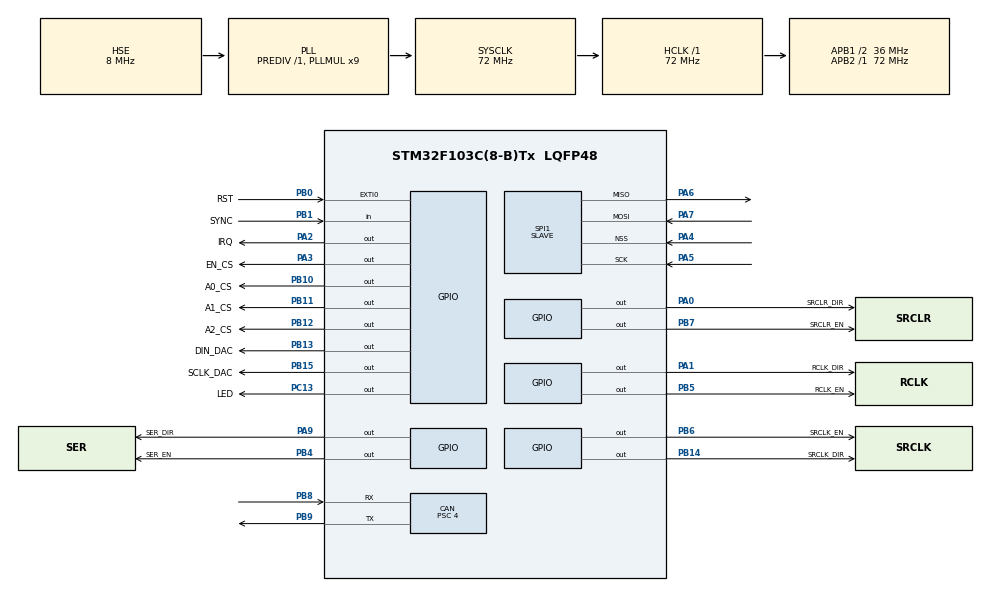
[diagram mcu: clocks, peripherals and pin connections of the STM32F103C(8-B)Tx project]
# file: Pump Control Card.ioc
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CAN.ABOM=ENABLE
CAN.BS1=CAN_BS1_15TQ
CAN.BS2=CAN_BS2_2TQ
CAN.CalculateBaudRate=500000
CAN.CalculateTimeBit=2000
CAN.CalculateTimeQuantum=111.11111111111111
CAN.NART=ENABLE
CAN.Prescaler=4
Mcu.Family=STM32F1
Mcu.Name=STM32F103C(8-B)Tx
Mcu.Package=LQFP48
NVIC.PriorityGroup=NVIC_PRIORITYGROUP_4
PA0-WKUP.GPIO_Label=SRCLR_DIR
PA0-WKUP.Signal=GPIO_Output
PA1.GPIO_Label=RCLK_DIR
PA1.Signal=GPIO_Output
PA13.Mode=Serial_Wire
PA13.Signal=SYS_JTMS-SWDIO
PA14.Mode=Serial_Wire
PA14.Signal=SYS_JTCK-SWCLK
PA2.GPIO_Label=IRQ
PA2.Signal=GPIO_Output
PA3.GPIO_Label=EN_CS
PA3.Signal=GPIO_Output
PA4.Mode=NSS_Signal_Hard_Input
PA4.Signal=SPI1_NSS
PA5.Mode=Full_Duplex_Slave
PA5.Signal=SPI1_SCK
PA6.Mode=Full_Duplex_Slave
PA6.Signal=SPI1_MISO
PA7.Mode=Full_Duplex_Slave
PA7.Signal=SPI1_MOSI
PA9.GPIO_Label=SER_DIR
PA9.Signal=GPIO_Output
PB0.GPIO_Label=RST
PB0.Signal=GPXTI0
PB1.GPIO_Label=SYNC
PB1.Signal=GPIO_Input
PB10.GPIO_Label=A0_CS
PB10.Signal=GPIO_Output
PB11.GPIO_Label=A1_CS
PB11.Signal=GPIO_Output
PB12.GPIO_Label=A2_CS
PB12.Signal=GPIO_Output
PB13.GPIO_Label=DIN_DAC
PB13.Signal=GPIO_Output
PB14.GPIO_Label=SRCLK_DIR
PB14.Signal=GPIO_Output
PB15.GPIO_Label=SCLK_DAC
PB15.Signal=GPIO_Output
PB4.GPIO_Label=SER_EN
PB4.Signal=GPIO_Output
PB5.GPIO_Label=RCLK_EN
PB5.Signal=GPIO_Output
PB6.GPIO_Label=SRCLK_EN
PB6.Signal=GPIO_Output
PB7.GPIO_Label=SRCLR_EN
PB7.Signal=GPIO_Output
PB8.Mode=CAN_Activate
PB8.Signal=CAN_RX
PB9.Mode=CAN_Activate
PB9.Signal=CAN_TX
PC13-TAMPER-RTC.GPIO_Label=LED
PC13-TAMPER-RTC.Signal=GPIO_Output
PC14-OSC32_IN.Mode=LSE-External-Oscillator
PC14-OSC32_IN.Signal=RCC_OSC32_IN
PC15-OSC32_OUT.Mode=LSE-External-Oscillator
PC15-OSC32_OUT.Signal=RCC_OSC32_OUT
PD0-OSC_IN.Mode=HSE-External-Oscillator
PD0-OSC_IN.Signal=RCC_OSC_IN
PD1-OSC_OUT.Mode=HSE-External-Oscillator
PD1-OSC_OUT.Signal=RCC_OSC_OUT
ProjectManager.HeapSize=0x200
ProjectManager.StackSize=0x400
ProjectManager.TargetToolchain=STM32CubeIDE
RCC.AHBFreq_Value=72000000
RCC.APB1CLKDivider=RCC_HCLK_DIV2
RCC.APB1Freq_Value=36000000
RCC.APB1TimFreq_Value=72000000
RCC.APB2Freq_Value=72000000
RCC.APB2TimFreq_Value=72000000
RCC.HCLKFreq_Value=72000000
RCC.PLLMUL=RCC_PLL_MUL9
RCC.PLLSourceVirtual=RCC_PLLSOURCE_HSE
RCC.SYSCLKFreq_VALUE=72000000
RCC.SYSCLKSource=RCC_SYSCLKSOURCE_PLLCLK
RCC.USBFreq_Value=72000000
SPI1.Direction=SPI_DIRECTION_2LINES
SPI1.Mode=SPI_MODE_SLAVE
SPI1.VirtualNSS=VM_NSSHARD
SPI1.VirtualType=VM_SLAVE
VP_RTC_No_RTC_Output.Mode=RTC_OUT_NO
VP_RTC_VS_RTC_Activate.Mode=RTC_Enabled
board=custom

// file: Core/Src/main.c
/* USER CODE BEGIN Header */
/**
  ******************************************************************************
  * @file           : main.c
  * @brief          : Main program body
  ******************************************************************************
  * @attention
  *
  * Copyright (c) 2026 STMicroelectronics.
  * All rights reserved.
  *
  * This software is licensed under terms that can be found in the LICENSE file
  * in the root directory of this software component.
  * If no LICENSE file comes with this software, it is provided AS-IS.
  *
  ******************************************************************************
  */
/* USER CODE END Header */
#include "main.h"
#include "can.h"
#include "rtc.h"
#include "spi.h"
#include "gpio.h"

/* USER CODE BEGIN Includes */
#include "pump_card_app.h"

/* USER CODE END Includes */

void SystemClock_Config(void);

int main(void)
{

  /* MCU Configuration--------------------------------------------------------*/

  /* Reset of all peripherals, Initializes the Flash interface and the Systick. */
  HAL_Init();

  /* Configure the system clock */
  SystemClock_Config();

  /* Initialize all configured peripherals */
  MX_GPIO_Init();
  MX_CAN_Init();
  MX_SPI1_Init();
  MX_RTC_Init();
  /* USER CODE BEGIN 2 */
  pump_card_app_init();

  /* USER CODE END 2 */

  /* Infinite loop */
  while (1)
  {

    /* USER CODE BEGIN 3 */
    pump_card_app_poll();
  }
  /* USER CODE END 3 */
}

void SystemClock_Config(void)
{
  RCC_OscInitTypeDef RCC_OscInitStruct = {0};
  RCC_ClkInitTypeDef RCC_ClkInitStruct = {0};
  RCC_PeriphCLKInitTypeDef PeriphClkInit = {0};

  /** Initializes the RCC Oscillators according to the specified parameters
  * in the RCC_OscInitTypeDef structure.
  */
  RCC_OscInitStruct.OscillatorType = RCC_OSCILLATORTYPE_LSI|RCC_OSCILLATORTYPE_HSE;
  RCC_OscInitStruct.HSEState = RCC_HSE_ON;
  RCC_OscInitStruct.HSEPredivValue = RCC_HSE_PREDIV_DIV1;
  RCC_OscInitStruct.HSIState = RCC_HSI_ON;
  RCC_OscInitStruct.LSIState = RCC_LSI_ON;
  RCC_OscInitStruct.PLL.PLLState = RCC_PLL_ON;
  RCC_OscInitStruct.PLL.PLLSource = RCC_PLLSOURCE_HSE;
  RCC_OscInitStruct.PLL.PLLMUL = RCC_PLL_MUL9;
  if (HAL_RCC_OscConfig(&RCC_OscInitStruct) != HAL_OK)
  {
    Error_Handler();
  }

  /** Initializes the CPU, AHB and APB buses clocks
  */
  RCC_ClkInitStruct.ClockType = RCC_CLOCKTYPE_HCLK|RCC_CLOCKTYPE_SYSCLK
                              |RCC_CLOCKTYPE_PCLK1|RCC_CLOCKTYPE_PCLK2;
  RCC_ClkInitStruct.SYSCLKSource = RCC_SYSCLKSOURCE_PLLCLK;
  RCC_ClkInitStruct.AHBCLKDivider = RCC_SYSCLK_DIV1;
  RCC_ClkInitStruct.APB1CLKDivider = RCC_HCLK_DIV2;
  RCC_ClkInitStruct.APB2CLKDivider = RCC_HCLK_DIV1;

  if (HAL_RCC_ClockConfig(&RCC_ClkInitStruct, FLASH_LATENCY_2) != HAL_OK)
  {
    Error_Handler();
  }
  PeriphClkInit.PeriphClockSelection = RCC_PERIPHCLK_RTC;
  PeriphClkInit.RTCClockSelection = RCC_RTCCLKSOURCE_LSI;
  if (HAL_RCCEx_PeriphCLKConfig(&PeriphClkInit) != HAL_OK)
  {
    Error_Handler();
  }
}

/* USER CODE BEGIN 4 */

void HAL_GPIO_EXTI_Callback(uint16_t GPIO_Pin)
{
  if (GPIO_Pin == SYNC_Pin)
  {
    pump_card_app_on_sync_edge();
  }
}

/* USER CODE END 4 */

void Error_Handler(void)
{
  __disable_irq();
  while (1)
  {
  }
}
